# EFM32GG11B520F2048IQ100 register map
File version: 4.0.0
CPU: CM4 r0p1, little endian, MPU, FPU, 3 interrupt priority bits
Registers are 32-bit, read-write, reset 0x0 unless marked. A register's access mark holds for its fields unless they carry their own. Offsets are from the block's base; [hi:lo] are bit positions; {n}, {i} and the like mark numbered series.

## IDAC0
Base 0x40084000
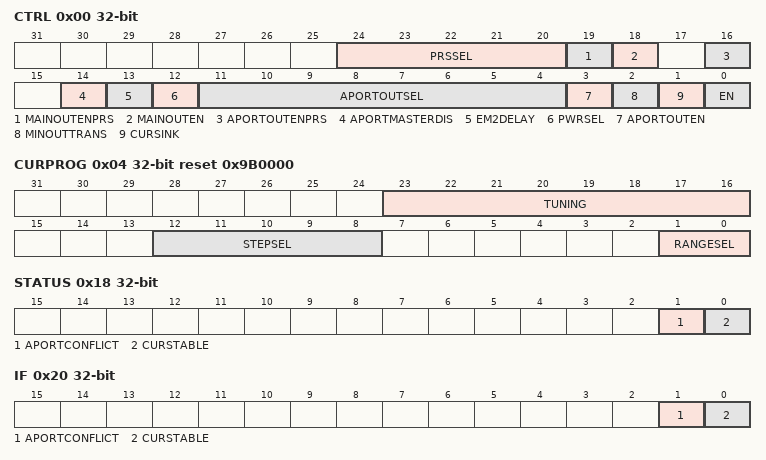
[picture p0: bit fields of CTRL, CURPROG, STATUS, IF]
0x00 CTRL — Control Register
  [24:20] PRSSEL — IDAC Output Enable PRS Channel Select
    {v}=PRSCH{v} (PRS Channel {v} selected.) (v=0..23)
  [19] MAINOUTENPRS — PRS Controlled Main Pad Output Enable
  [18] MAINOUTEN — Output Enable
  [16] APORTOUTENPRS — PRS Controlled APORT Output Enable
  [14] APORTMASTERDIS — APORT Bus Master Disable
  [13] EM2DELAY
  [12] PWRSEL — Power Select
  [11:4] APORTOUTSEL — APORT Output Select
    32=APORT1XCH0 (APORT1X Channel 0); 33=APORT1YCH1 (APORT1Y Channel 1); 34=APORT1XCH2 (APORT1X Channel 2); 35=APORT1YCH3 (APORT1Y Channel 3); 36=APORT1XCH4 (APORT1X Channel 4); 37=APORT1YCH5 (APORT1Y Channel 5); 38=APORT1XCH6 (APORT1X Channel 6); 39=APORT1YCH7 (APORT1Y Channel 7); 40=APORT1XCH8 (APORT1X Channel 8); 41=APORT1YCH9 (APORT1Y Channel 9); 42=APORT1XCH10 (APORT1X Channel 10); 43=APORT1YCH11 (APORT1Y Channel 11); 44=APORT1XCH12 (APORT1X Channel 12); 45=APORT1YCH13 (APORT1Y Channel 13); 46=APORT1XCH14 (APORT1X Channel 14); 47=APORT1YCH15 (APORT1Y Channel 15); 48=APORT1XCH16 (APORT1X Channel 16); 49=APORT1YCH17 (APORT1Y Channel 17); 50=APORT1XCH18 (APORT1X Channel 18); 51=APORT1YCH19 (APORT1Y Channel 19); 52=APORT1XCH20 (APORT1X Channel 20); 53=APORT1YCH21 (APORT1Y Channel 21); 54=APORT1XCH22 (APORT1X Channel 22); 55=APORT1YCH23 (APORT1Y Channel 23); 56=APORT1XCH24 (APORT1X Channel 24); 57=APORT1YCH25 (APORT1Y Channel 25); 58=APORT1XCH26 (APORT1X Channel 26); 59=APORT1YCH27 (APORT1Y Channel 27); 60=APORT1XCH28 (APORT1X Channel 28); 61=APORT1YCH29 (APORT1Y Channel 29); 62=APORT1XCH30 (APORT1X Channel 30); 63=APORT1YCH31 (APORT1Y Channel 31)
  [3] APORTOUTEN — APORT Output Enable
  [2] MINOUTTRANS — Minimum Output Transition Enable
  [1] CURSINK — Current Sink Enable
  [0] EN — Current DAC Enable
0x04 CURPROG reset 0x9B0000 — Current Programming Register
  [23:16] TUNING — Tune the Current to Given Accuracy
  [12:8] STEPSEL — Current Step Size Select
  [1:0] RANGESEL — Current Range Select
    0=RANGE0 (Current range set to 0 - 1.6 uA.); 1=RANGE1 (Current range set to 1.6 - 4.7 uA.); 2=RANGE2 (Current range set to 0.5 - 16 uA.); 3=RANGE3 (Current range set to 2 - 64 uA.)
0x0C DUTYCONFIG — Duty Cycle Configuration Register
  [1] EM2DUTYCYCLEDIS — Duty Cycle Enable
0x18 STATUS ro
  [1] APORTCONFLICT — APORT Conflict Output
  [0] CURSTABLE — IDAC Output Current Stable
0x20 IF ro — Interrupt Flag Register
  [1] APORTCONFLICT — APORT Conflict Interrupt Flag
  [0] CURSTABLE — Edge Triggered Interrupt Flag
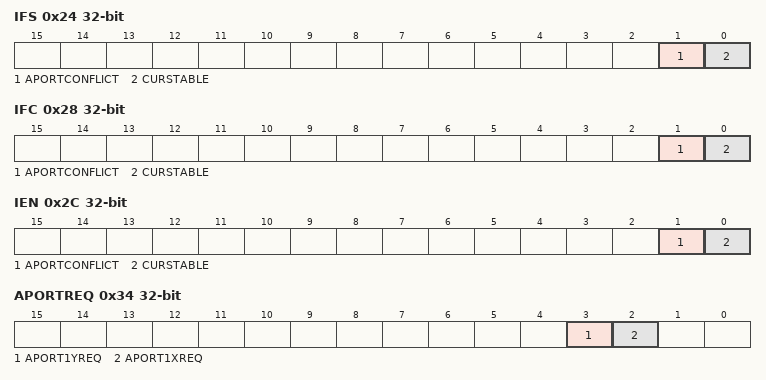
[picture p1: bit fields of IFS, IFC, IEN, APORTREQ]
0x24 IFS wo — Interrupt Flag Set Register
  [1] APORTCONFLICT — Set APORTCONFLICT Interrupt Flag
  [0] CURSTABLE — Set CURSTABLE Interrupt Flag
0x28 IFC wo — Interrupt Flag Clear Register
  [1] APORTCONFLICT — Clear APORTCONFLICT Interrupt Flag
  [0] CURSTABLE — Clear CURSTABLE Interrupt Flag
0x2C IEN — Interrupt Enable Register
  [1] APORTCONFLICT — APORTCONFLICT Interrupt Enable
  [0] CURSTABLE — CURSTABLE Interrupt Enable
0x34 APORTREQ ro — APORT Request Status Register
  [3] APORT1YREQ — 1 If the Bus Connected to APORT1Y is Requested
  [2] APORT1XREQ — 1 If the APORT Bus Connected to APORT1X is Requested
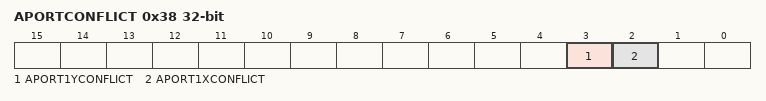
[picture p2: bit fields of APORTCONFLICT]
0x38 APORTCONFLICT ro — APORT Request Status Register
  [3] APORT1YCONFLICT — 1 If the Bus Connected to APORT1Y is in Conflict With Another Peripheral
  [2] APORT1XCONFLICT — 1 If the Bus Connected to APORT1X is in Conflict With Another Peripheral

## RTC
Base 0x40060000
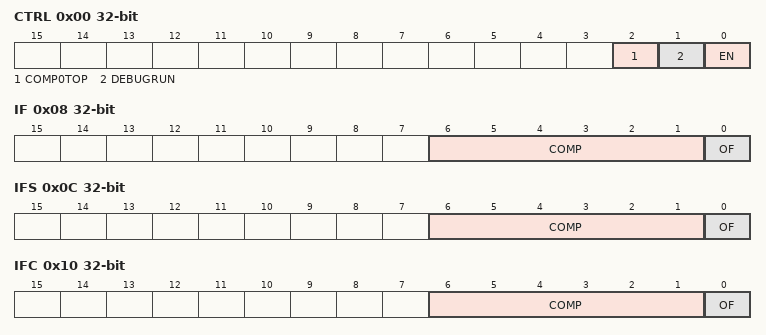
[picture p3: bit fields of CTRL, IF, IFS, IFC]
0x00 CTRL — Control Register
  [2] COMP0TOP — Compare Channel 0 is Top Value
  [1] DEBUGRUN — Debug Mode Run Enable
  [0] EN — RTC Enable
0x04 CNT — Counter Value Register
  [23:0] CNT — Counter Value
0x08 IF ro — Interrupt Flag Register
  [6:1] COMP — Compare Match X Interrupt Flag
  [0] OF — Overflow Interrupt Flag
0x0C IFS wo — Interrupt Flag Set Register
  [6:1] COMP — Set COMP Interrupt Flag
  [0] OF — Set OF Interrupt Flag
0x10 IFC wo — Interrupt Flag Clear Register
  [6:1] COMP — Clear COMP Interrupt Flag
  [0] OF — Clear OF Interrupt Flag
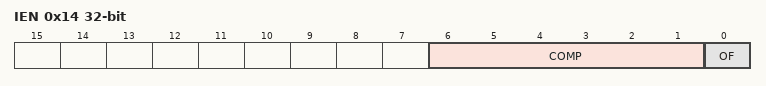
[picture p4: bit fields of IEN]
0x14 IEN — Interrupt Enable Register
  [6:1] COMP — COMP Interrupt Enable
  [0] OF — OF Interrupt Enable
0x20 COMPA_COMP — Compare Value Register X
  [23:0] COMP — Compare Value
0x24 COMPB_COMP — Compare Value Register X
  [23:0] COMP — Compare Value
0x28 COMPC_COMP — Compare Value Register X
  [23:0] COMP — Compare Value
0x2C COMPD_COMP — Compare Value Register X
  [23:0] COMP — Compare Value
0x30 COMPE_COMP — Compare Value Register X
  [23:0] COMP — Compare Value
0x34 COMPF_COMP — Compare Value Register X
  [23:0] COMP — Compare Value

## Notices in the file
# License
Copyright 2021 Silicon Laboratories Inc. www.silabs.com
SPDX-License-Identifier: Zlib
The licensor of this software is Silicon Laboratories Inc.
This software is provided 'as-is', without any express or implied
warranty. In no event will the authors be held liable for any damages
arising from the use of this software.
Permission is granted to anyone to use this software for any purpose,
including commercial applications, and to alter it and redistribute it
freely, subject to the following restrictions:
1. The origin of this software must not be misrepresented; you must not
claim that you wrote the original software. If you use this software
in a product, an acknowledgment in the product documentation would be
appreciated but is not required.
2. Altered source versions must be plainly marked as such, and must not be
misrepresented as being the original software.
3. This notice may not be removed or altered from any source distribution.
